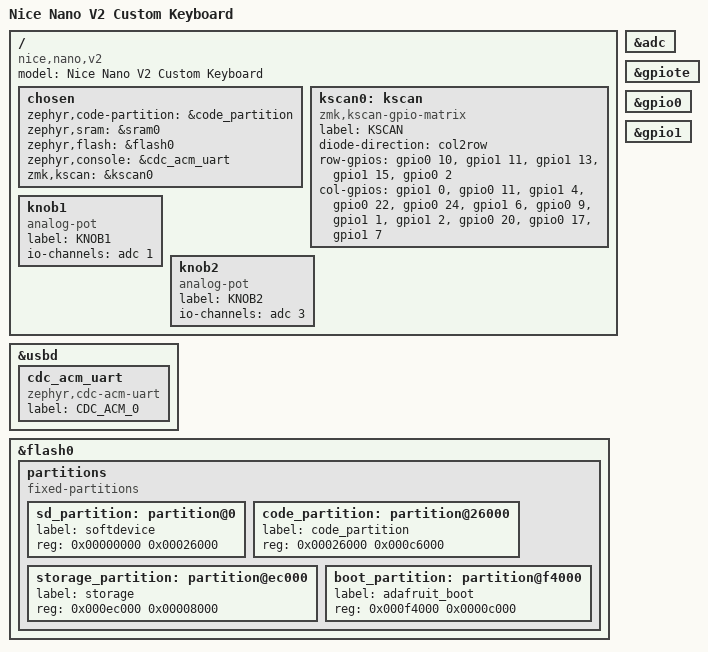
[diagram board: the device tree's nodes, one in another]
/*
 * Copyright (c) 2025
 * SPDX-License-Identifier: MIT
 */

/dts-v1/;
#include <nordic/nrf52840_qiaa.dtsi>

/ {
    model = "Nice Nano V2 Custom Keyboard";
    compatible = "nice,nano,v2";

    chosen {
        zephyr,code-partition = &code_partition;
        zephyr,sram = &sram0;
        zephyr,flash = &flash0;
        zephyr,console = &cdc_acm_uart;
        zmk,kscan = &kscan0;
    };

    kscan0: kscan {
        compatible = "zmk,kscan-gpio-matrix";
        label = "KSCAN";

        diode-direction = "col2row";

        row-gpios
            = <&gpio0 10 (GPIO_ACTIVE_HIGH | GPIO_PULL_DOWN)>  // r1: P0.10
            , <&gpio1 11 (GPIO_ACTIVE_HIGH | GPIO_PULL_DOWN)>  // r2: P1.11
            , <&gpio1 13 (GPIO_ACTIVE_HIGH | GPIO_PULL_DOWN)>  // r3: P1.13
            , <&gpio1 15 (GPIO_ACTIVE_HIGH | GPIO_PULL_DOWN)>  // r4: P1.15
            , <&gpio0 2  (GPIO_ACTIVE_HIGH | GPIO_PULL_DOWN)>  // r5: P0.02
            ;

        col-gpios
            = <&gpio1 0  GPIO_ACTIVE_HIGH>  // c1: P1.00
            , <&gpio0 11 GPIO_ACTIVE_HIGH>  // c2: P0.11
            , <&gpio1 4  GPIO_ACTIVE_HIGH>  // c3: P1.04
            , <&gpio0 22 GPIO_ACTIVE_HIGH>  // c4: P0.22
            , <&gpio0 24 GPIO_ACTIVE_HIGH>  // c5: P0.24
            , <&gpio1 6  GPIO_ACTIVE_HIGH>  // c6: P1.06
            , <&gpio0 9  GPIO_ACTIVE_HIGH>  // c7: P0.09
            , <&gpio1 1  GPIO_ACTIVE_HIGH>  // c8: P1.01
            , <&gpio1 2  GPIO_ACTIVE_HIGH>  // c9: P1.02
            , <&gpio0 20 GPIO_ACTIVE_HIGH>  // c10: P0.20
            , <&gpio0 17 GPIO_ACTIVE_HIGH>  // c11: P0.17
            , <&gpio1 7  GPIO_ACTIVE_HIGH>  // c12: P1.07
            ;
    };

    knob1: knob1 {
        compatible = "analog-pot";
        label = "KNOB1";
        io-channels = <&adc 1>;  // P0.29 = AIN1
    };

    knob2: knob2 {
        compatible = "analog-pot";
        label = "KNOB2";
        io-channels = <&adc 3>;  // P0.31 = AIN3
    };
};

&adc {
    status = "okay";
};

&gpiote {
    status = "okay";
};

&gpio0 {
    status = "okay";
};

&gpio1 {
    status = "okay";
};

&usbd {
    status = "okay";
    cdc_acm_uart: cdc_acm_uart {
        compatible = "zephyr,cdc-acm-uart";
        label = "CDC_ACM_0";
    };
};

&flash0 {
    partitions {
        compatible = "fixed-partitions";
        #address-cells = <1>;
        #size-cells = <1>;

        sd_partition: partition@0 {
            label = "softdevice";
            reg = <0x00000000 0x00026000>;
        };

        code_partition: partition@26000 {
            label = "code_partition";
            reg = <0x00026000 0x000c6000>;
        };

        storage_partition: partition@ec000 {
            label = "storage";
            reg = <0x000ec000 0x00008000>;
        };

        boot_partition: partition@f4000 {
            label = "adafruit_boot";
            reg = <0x000f4000 0x0000c000>;
        };
    };
};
